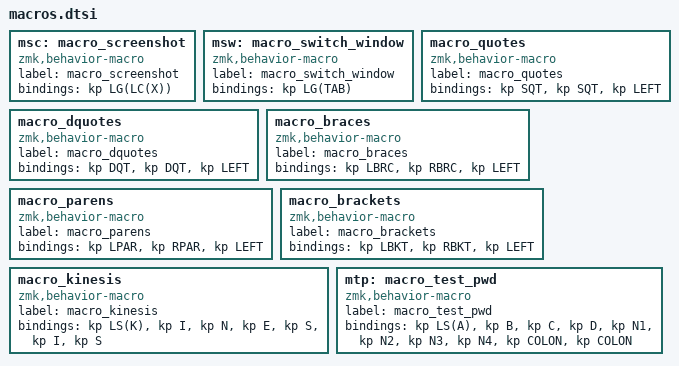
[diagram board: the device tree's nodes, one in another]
msc: macro_screenshot{
  compatible = "zmk,behavior-macro";
  label = "macro_screenshot";
  #binding-cells = <0>;
  bindings = <&kp LG(LC(X))>;
};
msw: macro_switch_window{
  compatible = "zmk,behavior-macro";
  label = "macro_switch_window";
  #binding-cells = <0>;
  bindings = <&kp LG(TAB)>;
};
macro_quotes: macro_quotes{
  compatible = "zmk,behavior-macro";
  label = "macro_quotes";
  #binding-cells = <0>;
  bindings = <&kp SQT>, <&kp SQT>, <&kp LEFT>;
};
macro_dquotes: macro_dquotes{
  compatible = "zmk,behavior-macro";
  label = "macro_dquotes";
  #binding-cells = <0>;
  bindings = <&kp DQT>, <&kp DQT>, <&kp LEFT>;
};
macro_braces: macro_braces{
  compatible = "zmk,behavior-macro";
  label = "macro_braces";
  #binding-cells = <0>;
  bindings = <&kp LBRC>, <&kp RBRC>, <&kp LEFT>;
};
macro_parens: macro_parens{
  compatible = "zmk,behavior-macro";
  label = "macro_parens";
  #binding-cells = <0>;
  bindings = <&kp LPAR>, <&kp RPAR>, <&kp LEFT>;
};
macro_brackets: macro_brackets{
  compatible = "zmk,behavior-macro";
  label = "macro_brackets";
  #binding-cells = <0>;
  bindings = <&kp LBKT>, <&kp RBKT>, <&kp LEFT>;
};
macro_kinesis: macro_kinesis{
  compatible = "zmk,behavior-macro";
  label = "macro_kinesis";
  #binding-cells = <0>;
  bindings = <&kp LS(K)>, <&kp I>, <&kp N>, <&kp E>, <&kp S>, <&kp I>, <&kp S>;
};
mtp: macro_test_pwd{
  compatible = "zmk,behavior-macro";
  label = "macro_test_pwd";
  #binding-cells = <0>;
  bindings = <&kp LS(A)>, <&kp B>, <&kp C>, <&kp D>, <&kp N1>, <&kp N2>, <&kp N3>, <&kp N4>, <&kp COLON>, <&kp COLON>;
};
